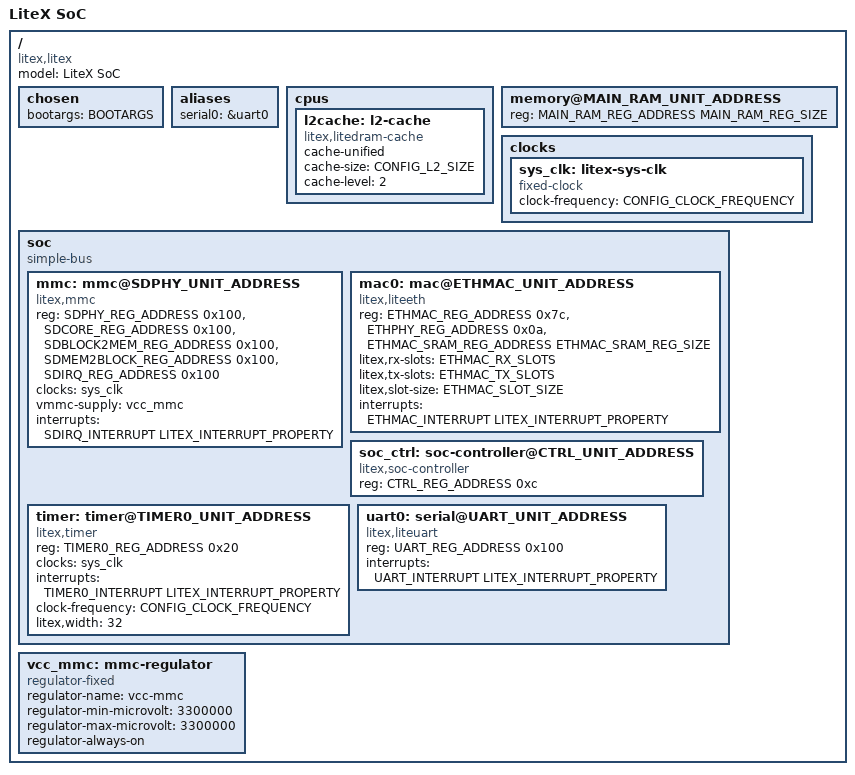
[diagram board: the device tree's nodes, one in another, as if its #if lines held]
/dts-v1/;

#ifdef CONFIG_CPU_TYPE_OPENC906
#include "dtsi/openc906.dtsi"
#endif

#ifndef LITEX_INTERRUPT_PROPERTY
#define LITEX_INTERRUPT_PROPERTY
#endif

/ {
	model = "LiteX SoC";
	compatible = "litex,litex";
	#address-cells = <1>;
	#size-cells = <1>;

	chosen {
#ifdef BOOTARGS
		bootargs = BOOTARGS;
#endif
	};

	aliases {
		serial0 = &uart0;
	};

	cpus {
		#address-cells = <1>;
		#size-cells	= <0>;

#ifdef CONFIG_L2_SIZE
		l2cache: l2-cache {
			compatible = "litex,litedram-cache", "cache";
			cache-unified;
			cache-size = <CONFIG_L2_SIZE>;
			cache-level = <2>;
		};
#endif
	};

	memory@MAIN_RAM_UNIT_ADDRESS {
		device_type = "memory";
		reg = <MAIN_RAM_REG_ADDRESS MAIN_RAM_REG_SIZE>;
	};

	clocks {
		sys_clk: litex-sys-clk {
			#clock-cells = <0>;
			compatible = "fixed-clock";
			clock-frequency = <CONFIG_CLOCK_FREQUENCY>;
		};
	};

	soc {
		#address-cells = <1>;
		#size-cells = <1>;
		compatible = "simple-bus";
		ranges;

#ifdef SDCORE_REG_ADDRESS
		mmc: mmc@SDPHY_UNIT_ADDRESS {
			compatible = "litex,mmc";
			reg = <SDPHY_REG_ADDRESS 0x100>,
			      <SDCORE_REG_ADDRESS 0x100>,
			      <SDBLOCK2MEM_REG_ADDRESS 0x100>,
			      <SDMEM2BLOCK_REG_ADDRESS 0x100>,
			      <SDIRQ_REG_ADDRESS 0x100>;
			reg-names = "phy", "core", "reader", "writer", "irq";
			clocks = <&sys_clk>;
			vmmc-supply = <&vcc_mmc>;
			interrupts = <SDIRQ_INTERRUPT LITEX_INTERRUPT_PROPERTY>;
		};
#endif

#if defined(ETHPHY_REG_ADDRESS) && defined(ETHMAC_REG_ADDRESS)
		mac0: mac@ETHMAC_UNIT_ADDRESS {
			compatible = "litex,liteeth";
			reg = <ETHMAC_REG_ADDRESS 0x7c>,
			      <ETHPHY_REG_ADDRESS 0x0a>,
			      <ETHMAC_SRAM_REG_ADDRESS ETHMAC_SRAM_REG_SIZE>;
			reg-names = "mac", "mdio", "buffer";
			litex,rx-slots = <ETHMAC_RX_SLOTS>;
			litex,tx-slots = <ETHMAC_TX_SLOTS>;
			litex,slot-size = <ETHMAC_SLOT_SIZE>;
			interrupts = <ETHMAC_INTERRUPT LITEX_INTERRUPT_PROPERTY>;
		};
#endif

		soc_ctrl: soc-controller@CTRL_UNIT_ADDRESS {
			compatible = "litex,soc-controller";
			reg = <CTRL_REG_ADDRESS 0xc>;
		};

		timer: timer@TIMER0_UNIT_ADDRESS {
			compatible = "litex,timer";
			reg = <TIMER0_REG_ADDRESS 0x20>;
			clocks = <&sys_clk>;
			interrupts = <TIMER0_INTERRUPT LITEX_INTERRUPT_PROPERTY>;
			clock-frequency = <CONFIG_CLOCK_FREQUENCY>;
			litex,width = <32>;
		};

		uart0: serial@UART_UNIT_ADDRESS {
			compatible = "litex,liteuart";
			reg = <UART_REG_ADDRESS 0x100>;
			interrupts = <UART_INTERRUPT LITEX_INTERRUPT_PROPERTY>;
		};
	};

#ifdef SDCORE_REG_ADDRESS
	vcc_mmc: mmc-regulator {
            compatible = "regulator-fixed";
            regulator-name = "vcc-mmc";
            regulator-min-microvolt = <3300000>;
            regulator-max-microvolt = <3300000>;
            regulator-always-on;
        };
#endif
};
